# ODS5010 register map
Vendor: OCS; Series: ODS5010; File version: 1.0
CPU: CM0plus r0p0, little endian, MPU, FPU, 4 interrupt priority bits
Registers are 32-bit, read-write, reset 0x0 unless marked. A register's access mark holds for its fields unless they carry their own. Offsets are from the block's base; [hi:lo] are bit positions; {n}, {i} and the like mark numbered series.

## RCC — Reset and Clock Control (RCC) Module
Base 0x40020000; register names take the prefix RCC_
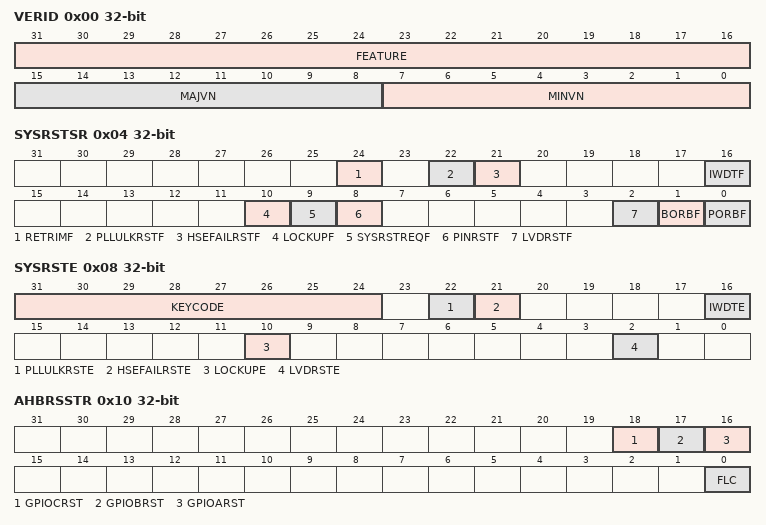
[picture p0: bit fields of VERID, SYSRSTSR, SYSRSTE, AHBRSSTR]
0x00 VERID — Version ID Register
  [31:16] FEATURE — Feature Identification Bits
  [15:8] MAJVN — Major Version Number
  [7:0] MINVN — Minor Version Number
0x04 SYSRSTSR — System Reset Status Register
  [24] RETRIMF — Re-trim Reset Flag
  [22] PLLULKRSTF — PLL Unlock Reset Flag
  [21] HSEFAILRSTF — HSE Fail Reset Flag
  [16] IWDTF — Independent Watchdog Reset Flag
  [10] LOCKUPF — Lockup Reset Flag
  [9] SYSRSTREQF — System Reset Request Flag
  [8] PINRSTF — Pin Reset Flag
  [2] LVDRSTF — Low Voltage Detect Reset Flag
  [1] BORBF — Brown-Out Reset Flag
  [0] PORBF — Power-On Reset Flag
0x08 SYSRSTE — System Reset Enable Register
  [31:24] KEYCODE — Write Protection Key Code
  [22] PLLULKRSTE — PLL Unlock Reset Enable
  [21] HSEFAILRSTE — HSE Fail Reset Enable
  [16] IWDTE — Independent Watchdog Reset Enable
  [10] LOCKUPE — Lockup Reset Enable
  [2] LVDRSTE — Low Voltage Detect Reset Enable
0x0C RSTKEY wo — Reset Key Register (write 0xAB56 to trigger boot reset and re-calibration)
  [15:0] RETRIM — Write 0xAB56 to trigger chip boot reset and re-run calibration
0x10 AHBRSSTR — AHB Peripheral Reset Register
  [18] GPIOCRST — GPIOC Reset
  [17] GPIOBRST — GPIOB Reset
  [16] GPIOARST — GPIOA Reset
  [0] FLC — Flash Controller Reset
0x14 ANARST — Analog Peripheral Reset Register
  [0] ADC_RST — ADC Reset
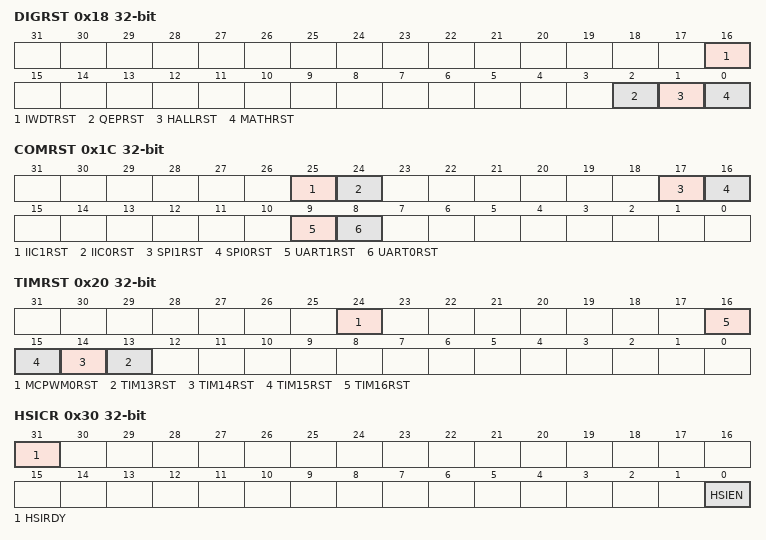
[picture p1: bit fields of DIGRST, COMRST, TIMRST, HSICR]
0x18 DIGRST — Digital Peripheral Reset Register
  [16] IWDTRST — Independent Watchdog Reset
  [2] QEPRST — QEP Module Reset
  [1] HALLRST — HALL Module Reset
  [0] MATHRST — MATH Module Reset
0x1C COMRST — Communication Peripheral Reset Register
  [25] IIC1RST — IIC1 Reset
  [24] IIC0RST — IIC0 Reset
  [17] SPI1RST — SPI1 Reset
  [16] SPI0RST — SPI0 Reset
  [9] UART1RST — UART1 Reset
  [8] UART0RST — UART0 Reset
0x20 TIMRST — Timer Peripheral Reset Register
  [24] MCPWM0RST — MCPWM Module Reset
  [n] TIM{n}RST (n=13..16) — TIM{n} Reset
0x24 RSV_0x24 — Reserved Register
0x28 RSV_0x28 — Reserved Register
0x2C RSV_0x2C — Reserved Register
0x30 HSICR — HSI Clock Control Register
  [31] HSIRDY — HSI Ready Flag
  [0] HSIEN — Internal 32MHz RC Clock Enable
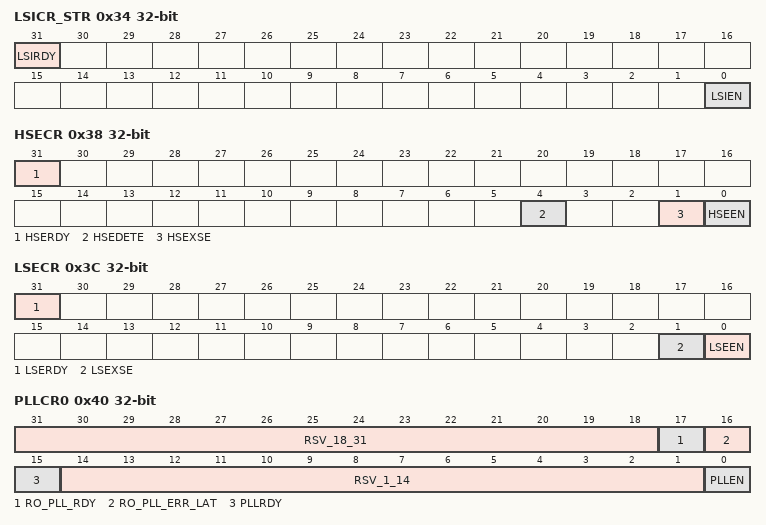
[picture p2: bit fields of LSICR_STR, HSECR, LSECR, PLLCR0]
0x34 LSICR_STR — LSI Clock Control Register
  [31] LSIRDY — LSI Ready Flag
  [0] LSIEN — Internal 32KHz RC Clock Enable
0x38 HSECR — HSE Clock Control Register
  [31] HSERDY — HSE Ready Flag
  [4] HSEDETE — HSE Fail Detection Enable
  [1] HSEXSE — HSE Bypass Enable
  [0] HSEEN — HSE Oscillator Enable
0x3C LSECR — LSE Clock Control Register
  [31] LSERDY — LSE Ready Flag
  [1] LSEXSE — LSE Bypass Enable
  [0] LSEEN — LSE Oscillator Enable
0x40 PLLCR0 — PLL Control Register 0
  [31:18] RSV_18_31 — Reserved Bits
  [17] RO_PLL_RDY — PLL Lock Ready Flag
  [16] RO_PLL_ERR_LAT — PLL Error Latch Flag
  [15] PLLRDY — PLL Enabled Ready Flag
  [14:1] RSV_1_14 — Reserved Bits
  [0] PLLEN — PLL Enable
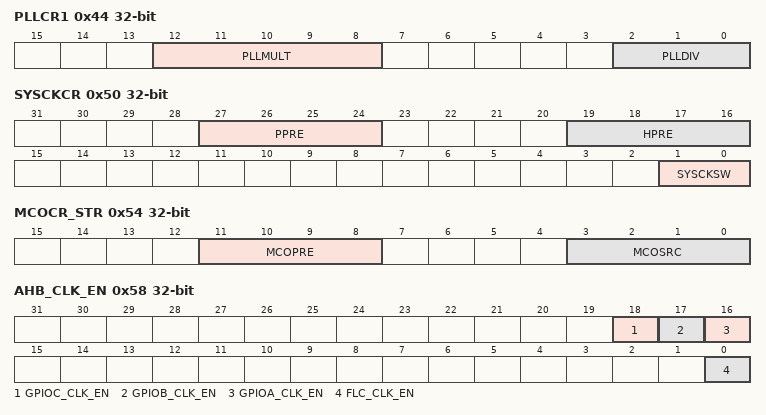
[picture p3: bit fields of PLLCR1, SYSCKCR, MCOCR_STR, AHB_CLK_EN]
0x44 PLLCR1 — PLL Control Register 1
  [12:8] PLLMULT — PLL Multiplication Factor
  [2:0] PLLDIV — PLL Output Divider
0x48 RSV_0x48 — Reserved Register
0x4C RSV_0x4C — Reserved Register
0x50 SYSCKCR — System Clock Control Register
  [27:24] PPRE — FCLK Prescaler (FCLK = SYSCLK / (HPRE + 1))
  [19:16] HPRE — PCLK Prescaler (PCLK = FCLK / (PPRE + 1))
  [1:0] SYSCKSW — System Clock Source Selection
0x54 MCOCR_STR — Microcontroller Clock Output Control Register
  [11:8] MCOPRE — MCO Prescaler (Output Frequency = Source / 2^MCOPRE)
  [3:0] MCOSRC — MCO Clock Source Selection
0x58 AHB_CLK_EN — AHB Peripheral Clock Enable Register
  [18] GPIOC_CLK_EN — GPIOC Clock Enable
  [17] GPIOB_CLK_EN — GPIOB Clock Enable
  [16] GPIOA_CLK_EN — GPIOA Clock Enable
  [0] FLC_CLK_EN — Flash Controller Clock Enable
0x5C ANA_CLK_EN — Analog Peripheral Clock Enable Register
  [0] ADC0_CLK_EN — ADC0 Clock Enable
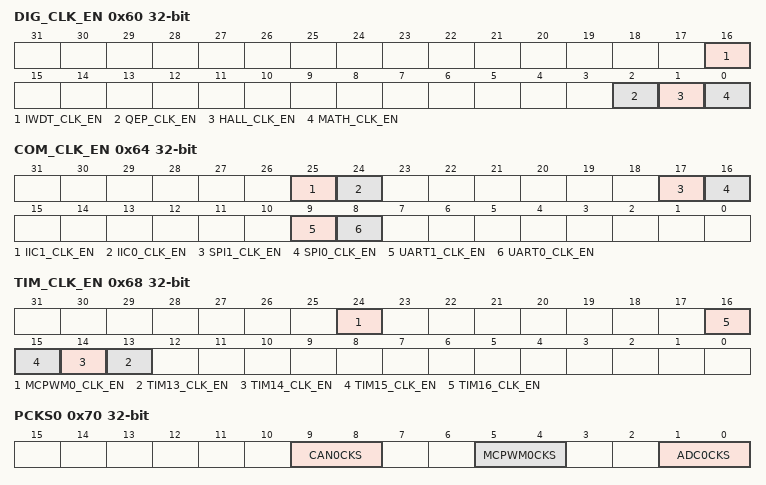
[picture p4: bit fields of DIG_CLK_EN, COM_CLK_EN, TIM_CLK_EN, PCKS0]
0x60 DIG_CLK_EN — Digital Peripheral Clock Enable Register
  [16] IWDT_CLK_EN — Independent Watchdog Clock Enable
  [2] QEP_CLK_EN — QEP Module Clock Enable
  [1] HALL_CLK_EN — HALL Module Clock Enable
  [0] MATH_CLK_EN — MATH Module Clock Enable
0x64 COM_CLK_EN — Communication Peripheral Clock Enable Register
  [25] IIC1_CLK_EN — IIC1 Clock Enable
  [24] IIC0_CLK_EN — IIC0 Clock Enable
  [17] SPI1_CLK_EN — SPI1 Clock Enable
  [16] SPI0_CLK_EN — SPI0 Clock Enable
  [9] UART1_CLK_EN — UART1 Clock Enable
  [8] UART0_CLK_EN — UART0 Clock Enable
0x68 TIM_CLK_EN — Timer Peripheral Clock Enable Register
  [24] MCPWM0_CLK_EN — MCPWM0 Clock Enable
  [n] TIM{n}_CLK_EN (n=13..16) — TIM{n} Clock Enable
0x6C RSV_0x6C — Reserved Register
0x70 PCKS0 — Peripheral Clock Source 0 Register
  [9:8] CAN0CKS — CAN Clock Source Selection
  [5:4] MCPWM0CKS — MCPWM Clock Source Selection
  [1:0] ADC0CKS — ADC Clock Source Selection
